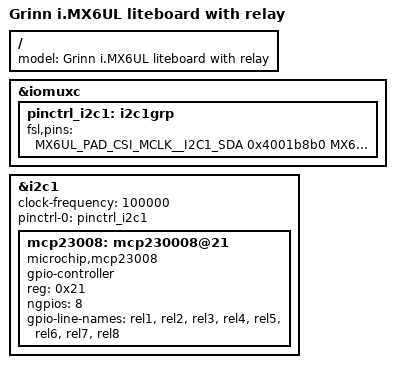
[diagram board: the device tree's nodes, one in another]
/*
 * Copyright 2017 Grinn
 *
 * Author: Michal Oleszczyk <m.oleszczyk@grinn-global.com>
 *
 * This file is dual-licensed: you can use it either under the terms
 * of the GPL or the X11 license, at your option. Note that this dual
 * licensing only applies to this file, and not this project as a
 * whole.
 *
 *  a) This file is free software; you can redistribute it and/or
 *     modify it under the terms of the GNU General Public License
 *     version 2 as published by the Free Software Foundation.
 *
 *     This file is distributed in the hope that it will be useful
 *     but WITHOUT ANY WARRANTY; without even the implied warranty of
 *     MERCHANTABILITY or FITNESS FOR A PARTICULAR PURPOSE.  See the
 *     GNU General Public License for more details.
 *
 * Or, alternatively
 *
 *  b) Permission is hereby granted, free of charge, to any person
 *     obtaining a copy of this software and associated documentation
 *     files (the "Software"), to deal in the Software without
 *     restriction, including without limitation the rights to use
 *     copy, modify, merge, publish, distribute, sublicense, and/or
 *     sell copies of the Software, and to permit persons to whom the
 *     Software is furnished to do so, subject to the following
 *     conditions:
 *
 *     The above copyright notice and this permission notice shall be
 *     included in all copies or substantial portions of the Software.
 *
 *     THE SOFTWARE IS PROVIDED , WITHOUT WARRANTY OF ANY KIND
 *     EXPRESS OR IMPLIED, INCLUDING BUT NOT LIMITED TO THE WARRANTIES
 *     OF MERCHANTABILITY, FITNESS FOR A PARTICULAR PURPOSE AND
 *     NONINFRINGEMENT. IN NO EVENT SHALL THE AUTHORS OR COPYRIGHT
 *     HOLDERS BE LIABLE FOR ANY CLAIM, DAMAGES OR OTHER LIABILITY
 *     WHETHER IN AN ACTION OF CONTRACT, TORT OR OTHERWISE, ARISING
 *     FROM, OUT OF OR IN CONNECTION WITH THE SOFTWARE OR THE USE OR
 *     OTHER DEALINGS IN THE SOFTWARE.
 */

#include "imx6ul-liteboard.dts"

/ {
	model = "Grinn i.MX6UL liteboard with relay";
};

&iomuxc {
	pinctrl_i2c1: i2c1grp {
		fsl,pins = <
			MX6UL_PAD_CSI_MCLK__I2C1_SDA   0x4001b8b0
			MX6UL_PAD_CSI_PIXCLK__I2C1_SCL 0x4001b8b0
		>;
	};
};

&i2c1 {
	clock-frequency = <100000>;
	pinctrl-names = "default";
	pinctrl-0 = <&pinctrl_i2c1>;
	status = "okay";

	mcp23008: mcp230008@21 {
		compatible = "microchip,mcp23008";
		gpio-controller;
		#gpio-cells = <2>;
		reg = <0x21>;

		ngpios = <8>;
		gpio-line-names = "rel1", "rel2", "rel3", "rel4",
			"rel5", "rel6", "rel7", "rel8";
	};
};
